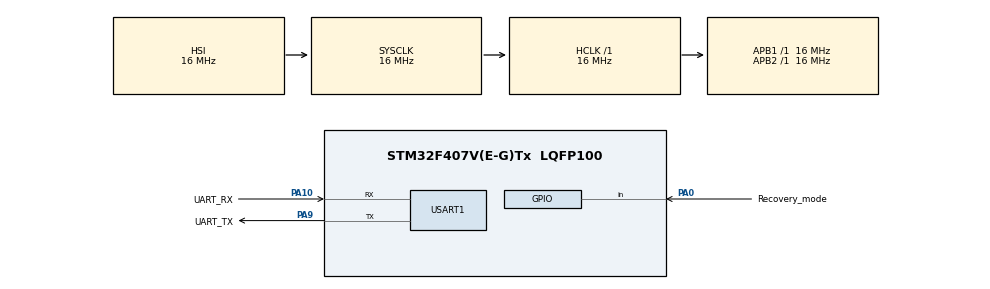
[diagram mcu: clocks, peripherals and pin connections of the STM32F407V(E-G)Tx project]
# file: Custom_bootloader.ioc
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IWDG.Prescaler=IWDG_PRESCALER_64
IWDG.Reload=3125
MBEDTLS.MBEDTLS_AES_C=0
MBEDTLS.MBEDTLS_AES_ROM_TABLES=0
MBEDTLS.MBEDTLS_ASN1_PARSE_C=1
MBEDTLS.MBEDTLS_BASE64_C=0
MBEDTLS.MBEDTLS_BIGNUM_C=1
MBEDTLS.MBEDTLS_CAMELLIA_C=0
MBEDTLS.MBEDTLS_CERTS_C=0
MBEDTLS.MBEDTLS_CHACHA20_C=0
MBEDTLS.MBEDTLS_CIPHER_MODE_OFB=0
MBEDTLS.MBEDTLS_CIPHER_MODE_XTS=0
MBEDTLS.MBEDTLS_ECDH_C=0
MBEDTLS.MBEDTLS_ECDSA_C=1
MBEDTLS.MBEDTLS_ECP_C=1
MBEDTLS.MBEDTLS_ECP_DP_CURVE448_ENABLED=0
MBEDTLS.MBEDTLS_ECP_DP_SECP384R1_ENABLED=0
MBEDTLS.MBEDTLS_ECP_MAX_BITS=256
MBEDTLS.MBEDTLS_ECP_NIST_OPTIM=0
MBEDTLS.MBEDTLS_ENTROPY_C=0
MBEDTLS.MBEDTLS_GCM_C=0
MBEDTLS.MBEDTLS_HAVE_ASM=0
MBEDTLS.MBEDTLS_HAVE_TIME=0
MBEDTLS.MBEDTLS_HKDF_C=0
MBEDTLS.MBEDTLS_MD_C=1
MBEDTLS.MBEDTLS_NO_DEFAULT_ENTROPY_SOURCES=0
MBEDTLS.MBEDTLS_NO_PLATFORM_ENTROPY=0
MBEDTLS.MBEDTLS_NO_UDBL_DIVISION=0
MBEDTLS.MBEDTLS_OID_C=0
MBEDTLS.MBEDTLS_PEM_PARSE_C=0
MBEDTLS.MBEDTLS_PLATFORM_C=1
MBEDTLS.MBEDTLS_POLY1305_C=0
MBEDTLS.MBEDTLS_REMOVE_3DES_CIPHERSUITES=0
MBEDTLS.MBEDTLS_SHA512_C=0
Mcu.Family=STM32F4
Mcu.Name=STM32F407V(E-G)Tx
Mcu.Package=LQFP100
NVIC.PriorityGroup=NVIC_PRIORITYGROUP_4
PA0-WKUP.GPIO_Label=Recovery_mode
PA0-WKUP.Signal=GPIO_Input
PA10.GPIO_Label=UART_RX
PA10.Mode=Asynchronous
PA10.Signal=USART1_RX
PA9.GPIO_Label=UART_TX
PA9.Mode=Asynchronous
PA9.Signal=USART1_TX
ProjectManager.HeapSize=0x200
ProjectManager.StackSize=0x400
ProjectManager.TargetToolchain=STM32CubeIDE
RCC.AHBFreq_Value=16000000
RCC.APB1Freq_Value=16000000
RCC.APB2Freq_Value=16000000
RCC.CortexFreq_Value=16000000
RCC.HSE_VALUE=25000000
RCC.HSI_VALUE=16000000
RCC.LSE_VALUE=32768
RCC.SYSCLKFreq_VALUE=16000000
RCC.VCOOutputFreq_Value=192000000
USART1.VirtualMode=VM_ASYNC
VP_IWDG_VS_IWDG.Mode=IWDG_Activate
VP_MBEDTLS_VS_MBEDTLS.Mode=Enabled
board=custom

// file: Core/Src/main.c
/* USER CODE BEGIN Header */
/**
  ******************************************************************************
  * @file           : main.c
  * @brief          : Main program body
  ******************************************************************************
  * @attention
  *
  * Copyright (c) 2026 STMicroelectronics.
  * All rights reserved.
  *
  * This software is licensed under terms that can be found in the LICENSE file
  * in the root directory of this software component.
  * If no LICENSE file comes with this software, it is provided AS-IS.
  *
  ******************************************************************************
  */
/* USER CODE END Header */
#include "main.h"
#include "mbedtls.h"

/* USER CODE BEGIN Includes */
#include "bootloader.h"
/* USER CODE END Includes */

IWDG_HandleTypeDef hiwdg;

UART_HandleTypeDef huart1;

void SystemClock_Config(void);
void MX_GPIO_Init(void);
void MX_IWDG_Init(void);
void MX_USART1_UART_Init(void);

int main(void)
{

  /* MCU Configuration--------------------------------------------------------*/

  /* Reset of all peripherals, Initializes the Flash interface and the Systick. */
  HAL_Init();

  /* Configure the system clock */
  SystemClock_Config();

  /* Initialize all configured peripherals */
  MX_GPIO_Init();
  MX_MBEDTLS_Init();
  MX_IWDG_Init();
  MX_USART1_UART_Init();
  /* USER CODE BEGIN 2 */

  /* Bootloader entry — this call should never return */
  Bootloader_Init();
  Bootloader_Run();

  /* USER CODE END 2 */

  /* Infinite loop */
  while (1)
  {

  }
}

void SystemClock_Config(void)
{
  RCC_OscInitTypeDef RCC_OscInitStruct = {0};
  RCC_ClkInitTypeDef RCC_ClkInitStruct = {0};

  /** Configure the main internal regulator output voltage
  */
  __HAL_RCC_PWR_CLK_ENABLE();
  __HAL_PWR_VOLTAGESCALING_CONFIG(PWR_REGULATOR_VOLTAGE_SCALE1);

  /** Initializes the RCC Oscillators according to the specified parameters
  * in the RCC_OscInitTypeDef structure.
  */
  RCC_OscInitStruct.OscillatorType = RCC_OSCILLATORTYPE_HSI|RCC_OSCILLATORTYPE_LSI;
  RCC_OscInitStruct.HSIState = RCC_HSI_ON;
  RCC_OscInitStruct.HSICalibrationValue = RCC_HSICALIBRATION_DEFAULT;
  RCC_OscInitStruct.LSIState = RCC_LSI_ON;
  RCC_OscInitStruct.PLL.PLLState = RCC_PLL_NONE;
  if (HAL_RCC_OscConfig(&RCC_OscInitStruct) != HAL_OK)
  {
    Error_Handler();
  }

  /** Initializes the CPU, AHB and APB buses clocks
  */
  RCC_ClkInitStruct.ClockType = RCC_CLOCKTYPE_HCLK|RCC_CLOCKTYPE_SYSCLK
                              |RCC_CLOCKTYPE_PCLK1|RCC_CLOCKTYPE_PCLK2;
  RCC_ClkInitStruct.SYSCLKSource = RCC_SYSCLKSOURCE_HSI;
  RCC_ClkInitStruct.AHBCLKDivider = RCC_SYSCLK_DIV1;
  RCC_ClkInitStruct.APB1CLKDivider = RCC_HCLK_DIV1;
  RCC_ClkInitStruct.APB2CLKDivider = RCC_HCLK_DIV1;

  if (HAL_RCC_ClockConfig(&RCC_ClkInitStruct, FLASH_LATENCY_0) != HAL_OK)
  {
    Error_Handler();
  }
}

void MX_IWDG_Init(void)
{

  hiwdg.Instance = IWDG;
  hiwdg.Init.Prescaler = IWDG_PRESCALER_64;
  hiwdg.Init.Reload = 3125;
  if (HAL_IWDG_Init(&hiwdg) != HAL_OK)
  {
    Error_Handler();
  }

}

void MX_USART1_UART_Init(void)
{

  huart1.Instance = USART1;
  huart1.Init.BaudRate = 115200;
  huart1.Init.WordLength = UART_WORDLENGTH_8B;
  huart1.Init.StopBits = UART_STOPBITS_1;
  huart1.Init.Parity = UART_PARITY_NONE;
  huart1.Init.Mode = UART_MODE_TX_RX;
  huart1.Init.HwFlowCtl = UART_HWCONTROL_NONE;
  huart1.Init.OverSampling = UART_OVERSAMPLING_16;
  if (HAL_UART_Init(&huart1) != HAL_OK)
  {
    Error_Handler();
  }

}

void MX_GPIO_Init(void)
{
  GPIO_InitTypeDef GPIO_InitStruct = {0};

  /* GPIO Ports Clock Enable */
  __HAL_RCC_GPIOA_CLK_ENABLE();

  /*Configure GPIO pin : Recovery_mode_Pin */
  GPIO_InitStruct.Pin = Recovery_mode_Pin;
  GPIO_InitStruct.Mode = GPIO_MODE_INPUT;
  GPIO_InitStruct.Pull = GPIO_PULLUP;   /* Must match recovery_mode.c */
  HAL_GPIO_Init(Recovery_mode_GPIO_Port, &GPIO_InitStruct);

}

void Error_Handler(void)
{
  __disable_irq();
  while (1)
  {
  }
}
